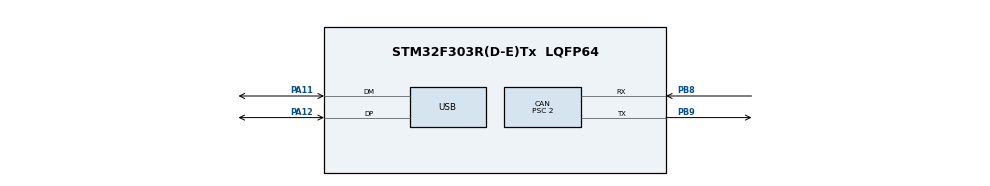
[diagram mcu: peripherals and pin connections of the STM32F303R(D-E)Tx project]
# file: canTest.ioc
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CAN.BS1=CAN_BS1_15TQ
CAN.BS2=CAN_BS2_2TQ
CAN.CalculateBaudRate=1000000
CAN.CalculateTimeBit=1000
CAN.CalculateTimeQuantum=55.55555555555556
CAN.Prescaler=2
Mcu.Family=STM32F3
Mcu.Name=STM32F303R(D-E)Tx
Mcu.Package=LQFP64
NVIC.CAN_RX1_IRQn=true\:0\:0\:false\:false\:true\:true\:true\:true
NVIC.PriorityGroup=NVIC_PRIORITYGROUP_4
NVIC.TIM8_UP_IRQn=true\:0\:0\:false\:false\:true\:true\:true\:true
NVIC.USB_LP_CAN_RX0_IRQn=true\:0\:0\:false\:false\:true\:true\:true\:true
NVIC.USB_LP_IRQn=true\:0\:0\:false\:false\:true\:false\:true\:true
PA11.Mode=Device
PA11.Signal=USB_DM
PA12.Mode=Device
PA12.Signal=USB_DP
PA13.Mode=Serial_Wire
PA13.Signal=SYS_JTMS-SWDIO
PA14.Mode=Serial_Wire
PA14.Signal=SYS_JTCK-SWCLK
PB8.Mode=CAN_Activate
PB8.Signal=CAN_RX
PB9.Mode=CAN_Activate
PB9.Signal=CAN_TX
PC14-OSC32_IN.Mode=LSE-External-Oscillator
PC14-OSC32_IN.Signal=RCC_OSC32_IN
PC15-OSC32_OUT.Mode=LSE-External-Oscillator
PC15-OSC32_OUT.Signal=RCC_OSC32_OUT
PF0-OSC_IN.Mode=HSE-External-Oscillator
PF0-OSC_IN.Signal=RCC_OSC_IN
PF1-OSC_OUT.Mode=HSE-External-Oscillator
PF1-OSC_OUT.Signal=RCC_OSC_OUT
ProjectManager.HeapSize=0x1000
ProjectManager.StackSize=0x1000
ProjectManager.TargetToolchain=STM32CubeIDE
RCC.AHBFreq_Value=72000000
RCC.APB1CLKDivider=RCC_HCLK_DIV2
RCC.APB1Freq_Value=36000000
RCC.APB1TimFreq_Value=72000000
RCC.APB2Freq_Value=72000000
RCC.APB2TimFreq_Value=72000000
RCC.CortexFreq_Value=72000000
RCC.HCLKFreq_Value=72000000
RCC.HSE_VALUE=8000000
RCC.HSI_VALUE=8000000
RCC.PLLMUL=RCC_PLL_MUL9
RCC.PRESCALERUSB=RCC_USBCLKSOURCE_PLL_DIV1_5
RCC.SYSCLKFreq_VALUE=72000000
RCC.SYSCLKSourceVirtual=RCC_SYSCLKSOURCE_PLLCLK
RCC.USBFreq_Value=48000000
TIM1.Period=1000
TIM1.Prescaler=72
TIM1.TIM_MasterOutputTrigger=TIM_TRGO_UPDATE
TIM1.TIM_MasterSlaveMode=TIM_MASTERSLAVEMODE_DISABLE
TIM8.Period=1000
USB_DEVICE.CLASS_NAME_FS=CDC
USB_DEVICE.VirtualMode=Cdc
USB_DEVICE.VirtualModeFS=Cdc_FS
VP_TIM1_VS_ClockSourceINT.Mode=Internal
VP_TIM8_VS_ClockSourceITR.Mode=TriggerSource_ITR0
VP_TIM8_VS_ControllerModeClock.Mode=Clock Mode
VP_USB_DEVICE_VS_USB_DEVICE_CDC_FS.Mode=CDC_FS
board=custom

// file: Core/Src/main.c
/* USER CODE BEGIN Header */
/**
  ******************************************************************************
  * @file           : main.c
  * @brief          : Main program body
  ******************************************************************************
  * @attention
  *
  * Copyright (c) 2023 STMicroelectronics.
  * All rights reserved.
  *
  * This software is licensed under terms that can be found in the LICENSE file
  * in the root directory of this software component.
  * If no LICENSE file comes with this software, it is provided AS-IS.
  *
  ******************************************************************************
  */
/* USER CODE END Header */
#include "main.h"
#include "can.h"
#include "tim.h"
#include "usb_device.h"
#include "gpio.h"

/* USER CODE BEGIN PV */
extern CAN_HandleTypeDef hcan;
/* USER CODE END PV */

void SystemClock_Config(void);

int main(void)
{

  /* MCU Configuration--------------------------------------------------------*/

  /* Reset of all peripherals, Initializes the Flash interface and the Systick. */
  HAL_Init();

  /* Configure the system clock */
  SystemClock_Config();

  /* Initialize all configured peripherals */
  MX_GPIO_Init();
  MX_CAN_Init();
  MX_TIM1_Init();
  MX_TIM8_Init();
  MX_USB_DEVICE_Init();
  /* USER CODE BEGIN 2 */

  altMain();
  /* USER CODE END 2 */

  /* Infinite loop */
  while (1)
  {

  }
}

void SystemClock_Config(void)
{
  LL_FLASH_SetLatency(LL_FLASH_LATENCY_2);
  while(LL_FLASH_GetLatency()!= LL_FLASH_LATENCY_2)
  {
  }
  LL_RCC_HSE_Enable();

   /* Wait till HSE is ready */
  while(LL_RCC_HSE_IsReady() != 1)
  {

  }
  LL_RCC_PLL_ConfigDomain_SYS(LL_RCC_PLLSOURCE_HSE, LL_RCC_PLL_MUL_9, LL_RCC_PREDIV_DIV_1);
  LL_RCC_PLL_Enable();

   /* Wait till PLL is ready */
  while(LL_RCC_PLL_IsReady() != 1)
  {

  }
  LL_RCC_SetAHBPrescaler(LL_RCC_SYSCLK_DIV_1);
  LL_RCC_SetAPB1Prescaler(LL_RCC_APB1_DIV_2);
  LL_RCC_SetAPB2Prescaler(LL_RCC_APB2_DIV_1);
  LL_RCC_SetSysClkSource(LL_RCC_SYS_CLKSOURCE_PLL);

   /* Wait till System clock is ready */
  while(LL_RCC_GetSysClkSource() != LL_RCC_SYS_CLKSOURCE_STATUS_PLL)
  {

  }
  LL_SetSystemCoreClock(72000000);

   /* Update the time base */
  if (HAL_InitTick (TICK_INT_PRIORITY) != HAL_OK)
  {
    Error_Handler();
  }
  LL_RCC_SetTIMClockSource(LL_RCC_TIM1_CLKSOURCE_PCLK2);
  LL_RCC_SetTIMClockSource(LL_RCC_TIM8_CLKSOURCE_PCLK2);
  LL_RCC_SetUSBClockSource(LL_RCC_USB_CLKSOURCE_PLL_DIV_1_5);
}

void Error_Handler(void)
{
  __disable_irq();
  while (1)
  {
  }
}
